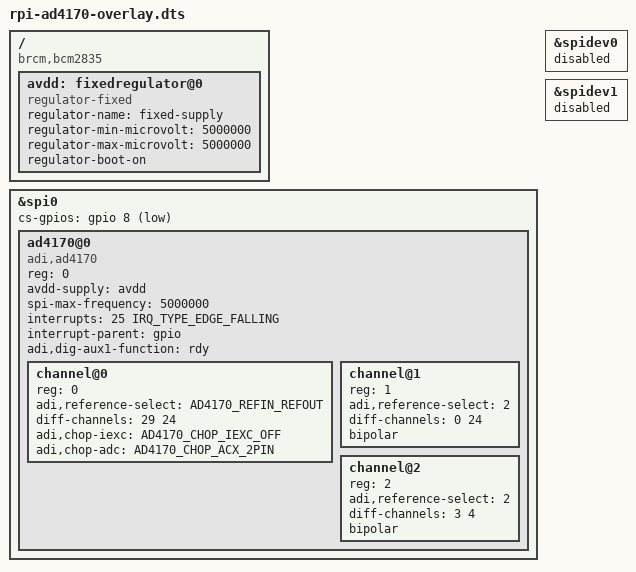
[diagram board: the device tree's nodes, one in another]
// SPDX-License-Identifier: GPL-2.0

/dts-v1/;
/plugin/;

#include <dt-bindings/gpio/gpio.h>
#include <dt-bindings/interrupt-controller/irq.h>
#include <dt-bindings/iio/adc/adi,ad4170.h>

/ 
{
	compatible = "brcm,bcm2835", "brcm,bcm2708", "brcm,bcm2709";

	fragment@0 {
		target-path = "/";
		__overlay__ {
			avdd: fixedregulator@0 {
				compatible = "regulator-fixed";
				regulator-name = "fixed-supply";
				regulator-min-microvolt = <5000000>;
				regulator-max-microvolt = <5000000>;
				regulator-boot-on;
			};
		};
	};

	fragment@1 {
		target = <&spi0>;
		__overlay__ {
			cs-gpios = <&gpio 8 GPIO_ACTIVE_LOW>;
			status = "okay";

		ad4170@0 {
			compatible = "adi,ad4170";
			reg = <0>;
			avdd-supply = <&avdd>;
			#address-cells = <1>;
			#size-cells = <0>;

			spi-max-frequency = <5000000>;
			interrupts = <25 IRQ_TYPE_EDGE_FALLING>;
			interrupt-parent = <&gpio>;
			interrupt-names = "adc_rdy";
			adi,dig-aux1-function = "rdy"; //AD4170_DIG_AUX1_RDY - syntax error;

			//adi,gpio0-power-down-switch;
			//adi,gpio1-power-down-switch;

			channel@0 {
				reg = <0>;

				adi,reference-select = <AD4170_REFIN_REFOUT>;

				/* REFOUT, DGND */
				diff-channels = <29 24>;
				adi,chop-iexc = <AD4170_CHOP_IEXC_OFF>;
				adi,chop-adc = <AD4170_CHOP_ACX_2PIN>;
			};

			channel@1 {
				reg = <1>;

				adi,reference-select = <2>;

				/* AIN0, DGND  */
				diff-channels = <0 24>;
				bipolar;
			};

			channel@2 {
				reg = <2>;

				adi,reference-select = <2>;

				/* AIN3+, AIN4-  */
				diff-channels = <3 4>;
				bipolar;
			};


			// channel@2 {
			// 	reg = <2>;

			// 	adi,reference-select = <2>;

			// 	/* Temperature Sensor, DGND */
			// 	diff-channels = <16 19>;
			// };

			// channel@3 {
			// 	reg = <3>;

			// 	adi,reference-select = <2>;

			// 	/* Internal reference, DGND */
			// 	diff-channels = <18 19>;
			// };

			// channel@4 {
			// 	reg = <4>;

			// 	adi,reference-select = <2>;

			// 	/* DGND, DGND */
			// 	diff-channels = <19 19>;
			// };
			};
		};
	};

	fragment@2 {
		target = <&spidev0>;
		__overlay__ {
			status = "disabled";
		};
	};

	fragment@3 {
		target = <&spidev1>;
		__overlay__ {
			status = "disabled";
		};
	};

};


